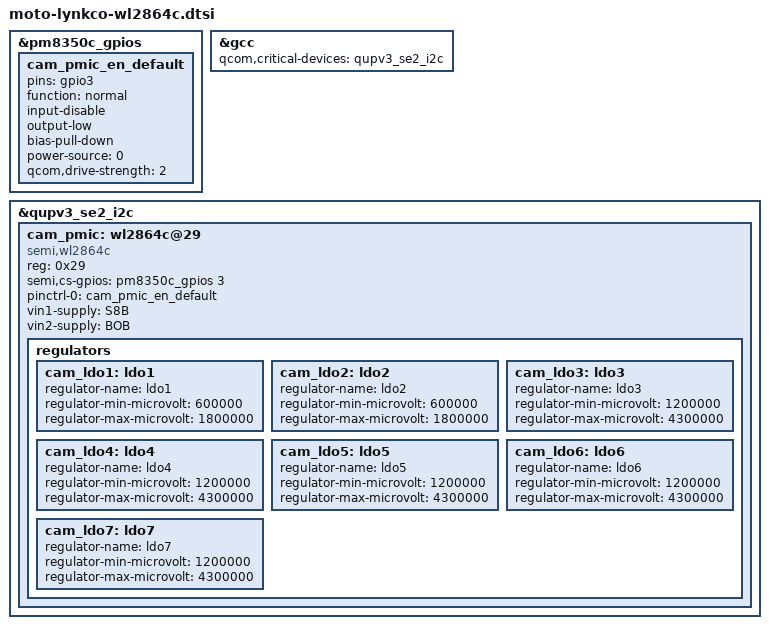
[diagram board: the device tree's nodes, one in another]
/*
 * Each QUP device that's a parent to PMIC must be listed as a critical device
 * to GCC.
 */

&pm8350c_gpios{
 	cam_pmic_en_default: cam_pmic_en_default {
 		pins = "gpio3";
		function = "normal";
		input-disable;
		output-low;
		bias-pull-down;
		power-source = <0>;	/* 1.8V */
		qcom,drive-strength = <2>;	/* Medium */
 	};
};

/*
 * Each QUP device that's a parent to PMIC must be listed as a critical device
 * to GCC.
 */
&gcc {
	qcom,critical-devices = <&qupv3_se2_i2c>;
};

&qupv3_se2_i2c {
	status = "ok";
	cam_pmic: wl2864c@29 {
		compatible = "semi,wl2864c";
		reg = <0x29>;

		semi,cs-gpios = <&pm8350c_gpios 3 0>;
		pinctrl-names = "default";
		pinctrl-0 = <&cam_pmic_en_default>;

		vin1-supply = <&S8B>;
		vin2-supply = <&BOB>;

		regulators {
			cam_ldo1: ldo1 {
				regulator-name = "ldo1";
				regulator-min-microvolt = <600000>;
				regulator-max-microvolt = <1800000>;
			};

			cam_ldo2: ldo2 {
				regulator-name = "ldo2";
				regulator-min-microvolt = <600000>;
				regulator-max-microvolt = <1800000>;
			};

			cam_ldo3: ldo3 {
				regulator-name = "ldo3";
				regulator-min-microvolt = <1200000>;
				regulator-max-microvolt = <4300000>;
			};

			cam_ldo4: ldo4 {
				regulator-name = "ldo4";
				regulator-min-microvolt = <1200000>;
				regulator-max-microvolt = <4300000>;
			};

			cam_ldo5: ldo5 {
				regulator-name = "ldo5";
				regulator-min-microvolt = <1200000>;
				regulator-max-microvolt = <4300000>;
			};

			cam_ldo6: ldo6 {
				regulator-name = "ldo6";
				regulator-min-microvolt = <1200000>;
				regulator-max-microvolt = <4300000>;
			};

			cam_ldo7: ldo7 {
				regulator-name = "ldo7";
				regulator-min-microvolt = <1200000>;
				regulator-max-microvolt = <4300000>;
			};
		};
	};
};
